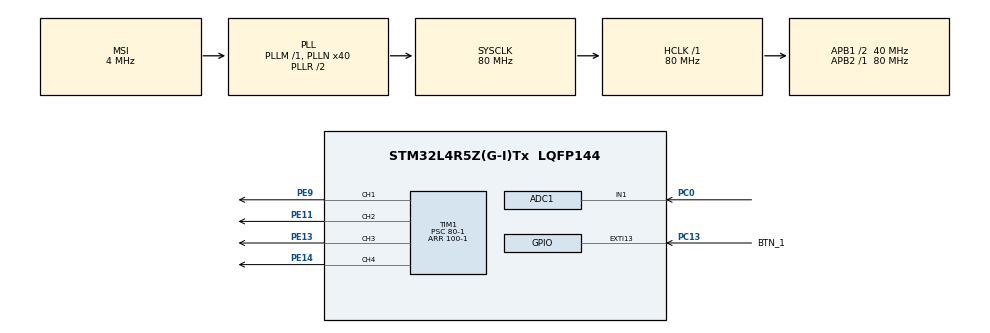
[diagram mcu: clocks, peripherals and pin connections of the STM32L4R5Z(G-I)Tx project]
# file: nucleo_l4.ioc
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ADC1.Channel-0\#ChannelRegularConversion=ADC_CHANNEL_1
ADC1.ClockPrescaler=ADC_CLOCK_ASYNC_DIV6
ADC1.NbrOfConversionFlag=1
ADC1.OffsetNumber-0\#ChannelRegularConversion=ADC_OFFSET_NONE
ADC1.Rank-0\#ChannelRegularConversion=1
ADC1.Resolution=ADC_RESOLUTION_12B
ADC1.SamplingTime-0\#ChannelRegularConversion=ADC_SAMPLETIME_2CYCLES_5
ADC1.master=1
Dma.ADC1.0.Direction=DMA_PERIPH_TO_MEMORY
Dma.ADC1.0.EventEnable=DISABLE
Dma.ADC1.0.Instance=DMA1_Channel1
Dma.ADC1.0.MemDataAlignment=DMA_MDATAALIGN_WORD
Dma.ADC1.0.MemInc=DMA_MINC_ENABLE
Dma.ADC1.0.Mode=DMA_NORMAL
Dma.ADC1.0.PeriphDataAlignment=DMA_PDATAALIGN_WORD
Dma.ADC1.0.PeriphInc=DMA_PINC_DISABLE
Dma.ADC1.0.Polarity=HAL_DMAMUX_REQUEST_GEN_RISING
Dma.ADC1.0.Priority=DMA_PRIORITY_LOW
Dma.ADC1.0.RequestNumber=1
Dma.ADC1.0.SignalID=NONE
Dma.ADC1.0.SyncEnable=DISABLE
Dma.ADC1.0.SyncPolarity=HAL_DMAMUX_SYNC_NO_EVENT
Dma.ADC1.0.SyncRequestNumber=1
Dma.ADC1.0.SyncSignalID=NONE
Dma.Request0=ADC1
Mcu.Family=STM32L4
Mcu.Name=STM32L4R5Z(G-I)Tx
Mcu.Package=LQFP144
NVIC.DMA1_Channel1_IRQn=true\:0\:0\:false\:false\:true\:false\:true\:true
NVIC.EXTI15_10_IRQn=true\:0\:0\:false\:false\:true\:true\:true\:true
NVIC.PriorityGroup=NVIC_PRIORITYGROUP_4
PA13\ (JTMS/SWDIO).GPIO_Label=TMS
PA13\ (JTMS/SWDIO).Mode=Trace_Asynchronous_SW
PA13\ (JTMS/SWDIO).Signal=SYS_JTMS-SWDIO
PA14\ (JTCK/SWCLK).GPIO_Label=TCK
PA14\ (JTCK/SWCLK).Mode=Trace_Asynchronous_SW
PA14\ (JTCK/SWCLK).Signal=SYS_JTCK-SWCLK
PB14.Signal=S_TIM15_CH1
PB3\ (JTDO/TRACESWO).GPIO_Label=SWO
PB3\ (JTDO/TRACESWO).Mode=Trace_Asynchronous_SW
PB3\ (JTDO/TRACESWO).Signal=SYS_JTDO-SWO
PB7.Signal=S_TIM4_CH2
PC0.Signal=ADCx_IN1
PC13.GPIO_Label=BTN_1
PC13.GPIO_ModeDefaultEXTI=GPIO_MODE_IT_FALLING
PC13.Signal=GPXTI13
PC14-OSC32_IN\ (PC14).Mode=LSE-External-Oscillator
PC14-OSC32_IN\ (PC14).Signal=RCC_OSC32_IN
PC15-OSC32_OUT\ (PC15).Mode=LSE-External-Oscillator
PC15-OSC32_OUT\ (PC15).Signal=RCC_OSC32_OUT
PC7.Signal=S_TIM8_CH2
PD8.GPIO_Label=STLK_RX [STM32F103CBT6_PA3]
PD8.Signal=USART3_TX
PD9.GPIO_Label=STLK_TX [STM32F103CBT6_PA2]
PD9.Signal=USART3_RX
PE11.Signal=S_TIM1_CH2
PE13.Signal=S_TIM1_CH3
PE14.Signal=S_TIM1_CH4
PE9.Signal=S_TIM1_CH1
PG7.GPIO_Label=STLINK_TX
PG7.Signal=LPUART1_TX
PG8.GPIO_Label=STLINK_RX
PG8.Signal=LPUART1_RX
PH0-OSC_IN\ (PH0).Mode=HSE-External-Clock-Source
PH0-OSC_IN\ (PH0).Signal=RCC_OSC_IN
PH1-OSC_OUT\ (PH1).Signal=RCC_OSC_OUT
ProjectManager.HeapSize=0x200
ProjectManager.StackSize=0x400
ProjectManager.TargetToolchain=STM32CubeIDE
RCC.48MHZClocksFreq_Value=24000000
RCC.ADCFreq_Value=80000000
RCC.AHBFreq_Value=80000000
RCC.APB1CLKDivider=RCC_HCLK_DIV2
RCC.APB1Freq_Value=40000000
RCC.APB1TimFreq_Value=80000000
RCC.APB2Freq_Value=80000000
RCC.APB2TimFreq_Value=80000000
RCC.CortexFreq_Value=80000000
RCC.HCLKFreq_Value=80000000
RCC.HSE_VALUE=8000000
RCC.HSI48_VALUE=48000000
RCC.HSI_VALUE=16000000
RCC.MSI_VALUE=4000000
RCC.PLLMUL=RCC_PLL_MUL9
RCC.PLLN=40
RCC.PLLSAI1N=40
RCC.PRESCALERUSB=RCC_USBCLKSOURCE_PLL_DIV1_5
RCC.SYSCLKFreq_VALUE=80000000
RCC.SYSCLKSource=RCC_SYSCLKSOURCE_PLLCLK
RCC.SYSCLKSourceVirtual=RCC_SYSCLKSOURCE_PLLCLK
RCC.USBFreq_Value=80000000
RCC.VCOOutputFreq_Value=160000000
SH.ADCx_IN1.0=ADC1_IN1,IN1-Single-Ended
SH.S_TIM15_CH1.0=TIM15_CH1
SH.S_TIM1_CH1.0=TIM1_CH1,PWM Generation1 CH1
SH.S_TIM1_CH2.0=TIM1_CH2,PWM Generation2 CH2
SH.S_TIM1_CH3.0=TIM1_CH3,PWM Generation3 CH3
SH.S_TIM1_CH4.0=TIM1_CH4,PWM Generation4 CH4
SH.S_TIM4_CH2.0=TIM4_CH2
SH.S_TIM8_CH2.0=TIM8_CH2
TIM1.Channel-PWM\ Generation1\ CH1=TIM_CHANNEL_1
TIM1.Channel-PWM\ Generation2\ CH2=TIM_CHANNEL_2
TIM1.Channel-PWM\ Generation3\ CH3=TIM_CHANNEL_3
TIM1.Channel-PWM\ Generation4\ CH4=TIM_CHANNEL_4
TIM1.CounterMode=TIM_COUNTERMODE_UP
TIM1.Period=100-1
TIM1.Prescaler=80-1
board=NUCLEO-L4R5ZI

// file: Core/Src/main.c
/* USER CODE BEGIN Header */
/**
  ******************************************************************************
  * @file           : main.c
  * @brief          : Main program body
  ******************************************************************************
  * @attention
  *
  * Copyright (c) 2025 STMicroelectronics.
  * All rights reserved.
  *
  * This software is licensed under terms that can be found in the LICENSE file
  * in the root directory of this software component.
  * If no LICENSE file comes with this software, it is provided AS-IS.
  *
  ******************************************************************************
  */
/* USER CODE END Header */
#include "main.h"

/* USER CODE BEGIN Includes */
#include "lazer_isaretleyici.h"
/* USER CODE END Includes */

ADC_HandleTypeDef hadc1;
DMA_HandleTypeDef hdma_adc1;

TIM_HandleTypeDef htim1;

void SystemClock_Config(void);
static void MX_GPIO_Init(void);
static void MX_DMA_Init(void);
static void MX_TIM1_Init(void);
static void MX_ADC1_Init(void);

int main(void)
{

  /* MCU Configuration--------------------------------------------------------*/

  /* Reset of all peripherals, Initializes the Flash interface and the Systick. */
  HAL_Init();

  /* Configure the system clock */
  SystemClock_Config();

  /* Initialize all configured peripherals */
  MX_GPIO_Init();
  MX_DMA_Init();
  MX_TIM1_Init();
  MX_ADC1_Init();
  /* USER CODE BEGIN 2 */
  StartPWM();

  /* USER CODE END 2 */

  /* Infinite loop */
  /* USER CODE BEGIN WHILE */

  while (1)
  {
	  DeviceModeHandler();
	  ChangeDeviceMode(adcbuffer);
    /* USER CODE END WHILE */

  }
}

void SystemClock_Config(void)
{
  RCC_OscInitTypeDef RCC_OscInitStruct = {0};
  RCC_ClkInitTypeDef RCC_ClkInitStruct = {0};

  /** Configure the main internal regulator output voltage
  */
  if (HAL_PWREx_ControlVoltageScaling(PWR_REGULATOR_VOLTAGE_SCALE1) != HAL_OK)
  {
    Error_Handler();
  }

  /** Initializes the RCC Oscillators according to the specified parameters
  * in the RCC_OscInitTypeDef structure.
  */
  RCC_OscInitStruct.OscillatorType = RCC_OSCILLATORTYPE_MSI;
  RCC_OscInitStruct.MSIState = RCC_MSI_ON;
  RCC_OscInitStruct.MSICalibrationValue = 0;
  RCC_OscInitStruct.MSIClockRange = RCC_MSIRANGE_6;
  RCC_OscInitStruct.PLL.PLLState = RCC_PLL_ON;
  RCC_OscInitStruct.PLL.PLLSource = RCC_PLLSOURCE_MSI;
  RCC_OscInitStruct.PLL.PLLM = 1;
  RCC_OscInitStruct.PLL.PLLN = 40;
  RCC_OscInitStruct.PLL.PLLP = RCC_PLLP_DIV2;
  RCC_OscInitStruct.PLL.PLLQ = RCC_PLLQ_DIV2;
  RCC_OscInitStruct.PLL.PLLR = RCC_PLLR_DIV2;
  if (HAL_RCC_OscConfig(&RCC_OscInitStruct) != HAL_OK)
  {
    Error_Handler();
  }

  /** Initializes the CPU, AHB and APB buses clocks
  */
  RCC_ClkInitStruct.ClockType = RCC_CLOCKTYPE_HCLK|RCC_CLOCKTYPE_SYSCLK
                              |RCC_CLOCKTYPE_PCLK1|RCC_CLOCKTYPE_PCLK2;
  RCC_ClkInitStruct.SYSCLKSource = RCC_SYSCLKSOURCE_PLLCLK;
  RCC_ClkInitStruct.AHBCLKDivider = RCC_SYSCLK_DIV1;
  RCC_ClkInitStruct.APB1CLKDivider = RCC_HCLK_DIV2;
  RCC_ClkInitStruct.APB2CLKDivider = RCC_HCLK_DIV1;

  if (HAL_RCC_ClockConfig(&RCC_ClkInitStruct, FLASH_LATENCY_3) != HAL_OK)
  {
    Error_Handler();
  }
}

static void MX_ADC1_Init(void)
{

  ADC_ChannelConfTypeDef sConfig = {0};

  /** Common config
  */
  hadc1.Instance = ADC1;
  hadc1.Init.ClockPrescaler = ADC_CLOCK_ASYNC_DIV6;
  hadc1.Init.Resolution = ADC_RESOLUTION_12B;
  hadc1.Init.DataAlign = ADC_DATAALIGN_RIGHT;
  hadc1.Init.ScanConvMode = ADC_SCAN_DISABLE;
  hadc1.Init.EOCSelection = ADC_EOC_SINGLE_CONV;
  hadc1.Init.LowPowerAutoWait = DISABLE;
  hadc1.Init.ContinuousConvMode = DISABLE;
  hadc1.Init.NbrOfConversion = 1;
  hadc1.Init.DiscontinuousConvMode = DISABLE;
  hadc1.Init.ExternalTrigConv = ADC_SOFTWARE_START;
  hadc1.Init.ExternalTrigConvEdge = ADC_EXTERNALTRIGCONVEDGE_NONE;
  hadc1.Init.DMAContinuousRequests = DISABLE;
  hadc1.Init.Overrun = ADC_OVR_DATA_PRESERVED;
  hadc1.Init.OversamplingMode = DISABLE;
  if (HAL_ADC_Init(&hadc1) != HAL_OK)
  {
    Error_Handler();
  }

  /** Configure Regular Channel
  */
  sConfig.Channel = ADC_CHANNEL_1;
  sConfig.Rank = ADC_REGULAR_RANK_1;
  sConfig.SamplingTime = ADC_SAMPLETIME_2CYCLES_5;
  sConfig.SingleDiff = ADC_SINGLE_ENDED;
  sConfig.OffsetNumber = ADC_OFFSET_NONE;
  sConfig.Offset = 0;
  if (HAL_ADC_ConfigChannel(&hadc1, &sConfig) != HAL_OK)
  {
    Error_Handler();
  }

}

static void MX_TIM1_Init(void)
{

  TIM_MasterConfigTypeDef sMasterConfig = {0};
  TIM_OC_InitTypeDef sConfigOC = {0};
  TIM_BreakDeadTimeConfigTypeDef sBreakDeadTimeConfig = {0};

  htim1.Instance = TIM1;
  htim1.Init.Prescaler = 80-1;
  htim1.Init.CounterMode = TIM_COUNTERMODE_UP;
  htim1.Init.Period = 100-1;
  htim1.Init.ClockDivision = TIM_CLOCKDIVISION_DIV1;
  htim1.Init.RepetitionCounter = 0;
  htim1.Init.AutoReloadPreload = TIM_AUTORELOAD_PRELOAD_DISABLE;
  if (HAL_TIM_PWM_Init(&htim1) != HAL_OK)
  {
    Error_Handler();
  }
  sMasterConfig.MasterOutputTrigger = TIM_TRGO_RESET;
  sMasterConfig.MasterOutputTrigger2 = TIM_TRGO2_RESET;
  sMasterConfig.MasterSlaveMode = TIM_MASTERSLAVEMODE_DISABLE;
  if (HAL_TIMEx_MasterConfigSynchronization(&htim1, &sMasterConfig) != HAL_OK)
  {
    Error_Handler();
  }
  sConfigOC.OCMode = TIM_OCMODE_PWM1;
  sConfigOC.Pulse = 0;
  sConfigOC.OCPolarity = TIM_OCPOLARITY_HIGH;
  sConfigOC.OCNPolarity = TIM_OCNPOLARITY_HIGH;
  sConfigOC.OCFastMode = TIM_OCFAST_DISABLE;
  sConfigOC.OCIdleState = TIM_OCIDLESTATE_RESET;
  sConfigOC.OCNIdleState = TIM_OCNIDLESTATE_RESET;
  if (HAL_TIM_PWM_ConfigChannel(&htim1, &sConfigOC, TIM_CHANNEL_1) != HAL_OK)
  {
    Error_Handler();
  }
  if (HAL_TIM_PWM_ConfigChannel(&htim1, &sConfigOC, TIM_CHANNEL_2) != HAL_OK)
  {
    Error_Handler();
  }
  if (HAL_TIM_PWM_ConfigChannel(&htim1, &sConfigOC, TIM_CHANNEL_3) != HAL_OK)
  {
    Error_Handler();
  }
  if (HAL_TIM_PWM_ConfigChannel(&htim1, &sConfigOC, TIM_CHANNEL_4) != HAL_OK)
  {
    Error_Handler();
  }
  sBreakDeadTimeConfig.OffStateRunMode = TIM_OSSR_DISABLE;
  sBreakDeadTimeConfig.OffStateIDLEMode = TIM_OSSI_DISABLE;
  sBreakDeadTimeConfig.LockLevel = TIM_LOCKLEVEL_OFF;
  sBreakDeadTimeConfig.DeadTime = 0;
  sBreakDeadTimeConfig.BreakState = TIM_BREAK_DISABLE;
  sBreakDeadTimeConfig.BreakPolarity = TIM_BREAKPOLARITY_HIGH;
  sBreakDeadTimeConfig.BreakFilter = 0;
  sBreakDeadTimeConfig.Break2State = TIM_BREAK2_DISABLE;
  sBreakDeadTimeConfig.Break2Polarity = TIM_BREAK2POLARITY_HIGH;
  sBreakDeadTimeConfig.Break2Filter = 0;
  sBreakDeadTimeConfig.AutomaticOutput = TIM_AUTOMATICOUTPUT_DISABLE;
  if (HAL_TIMEx_ConfigBreakDeadTime(&htim1, &sBreakDeadTimeConfig) != HAL_OK)
  {
    Error_Handler();
  }
  HAL_TIM_MspPostInit(&htim1);

}

static void MX_DMA_Init(void)
{

  /* DMA controller clock enable */
  __HAL_RCC_DMAMUX1_CLK_ENABLE();
  __HAL_RCC_DMA1_CLK_ENABLE();

  /* DMA interrupt init */
  /* DMA1_Channel1_IRQn interrupt configuration */
  HAL_NVIC_SetPriority(DMA1_Channel1_IRQn, 0, 0);
  HAL_NVIC_EnableIRQ(DMA1_Channel1_IRQn);

}

static void MX_GPIO_Init(void)
{
  GPIO_InitTypeDef GPIO_InitStruct = {0};

  /* GPIO Ports Clock Enable */
  __HAL_RCC_GPIOC_CLK_ENABLE();
  __HAL_RCC_GPIOH_CLK_ENABLE();
  __HAL_RCC_GPIOE_CLK_ENABLE();
  __HAL_RCC_GPIOB_CLK_ENABLE();
  __HAL_RCC_GPIOD_CLK_ENABLE();
  __HAL_RCC_GPIOG_CLK_ENABLE();
  HAL_PWREx_EnableVddIO2();
  __HAL_RCC_GPIOA_CLK_ENABLE();

  /*Configure GPIO pin : BTN_1_Pin */
  GPIO_InitStruct.Pin = BTN_1_Pin;
  GPIO_InitStruct.Mode = GPIO_MODE_IT_FALLING;
  GPIO_InitStruct.Pull = GPIO_NOPULL;
  HAL_GPIO_Init(BTN_1_GPIO_Port, &GPIO_InitStruct);

  /*Configure GPIO pin : PB14 */
  GPIO_InitStruct.Pin = GPIO_PIN_14;
  GPIO_InitStruct.Mode = GPIO_MODE_AF_PP;
  GPIO_InitStruct.Pull = GPIO_NOPULL;
  GPIO_InitStruct.Speed = GPIO_SPEED_FREQ_LOW;
  GPIO_InitStruct.Alternate = GPIO_AF14_TIM15;
  HAL_GPIO_Init(GPIOB, &GPIO_InitStruct);

  /*Configure GPIO pins : STLK_RX_Pin STLK_TX_Pin */
  GPIO_InitStruct.Pin = STLK_RX_Pin|STLK_TX_Pin;
  GPIO_InitStruct.Mode = GPIO_MODE_AF_PP;
  GPIO_InitStruct.Pull = GPIO_NOPULL;
  GPIO_InitStruct.Speed = GPIO_SPEED_FREQ_VERY_HIGH;
  GPIO_InitStruct.Alternate = GPIO_AF7_USART3;
  HAL_GPIO_Init(GPIOD, &GPIO_InitStruct);

  /*Configure GPIO pins : STLINK_TX_Pin STLINK_RX_Pin */
  GPIO_InitStruct.Pin = STLINK_TX_Pin|STLINK_RX_Pin;
  GPIO_InitStruct.Mode = GPIO_MODE_AF_PP;
  GPIO_InitStruct.Pull = GPIO_NOPULL;
  GPIO_InitStruct.Speed = GPIO_SPEED_FREQ_VERY_HIGH;
  GPIO_InitStruct.Alternate = GPIO_AF8_LPUART1;
  HAL_GPIO_Init(GPIOG, &GPIO_InitStruct);

  /*Configure GPIO pin : PC7 */
  GPIO_InitStruct.Pin = GPIO_PIN_7;
  GPIO_InitStruct.Mode = GPIO_MODE_AF_PP;
  GPIO_InitStruct.Pull = GPIO_NOPULL;
  GPIO_InitStruct.Speed = GPIO_SPEED_FREQ_LOW;
  GPIO_InitStruct.Alternate = GPIO_AF3_TIM8;
  HAL_GPIO_Init(GPIOC, &GPIO_InitStruct);

  /*Configure GPIO pin : PB7 */
  GPIO_InitStruct.Pin = GPIO_PIN_7;
  GPIO_InitStruct.Mode = GPIO_MODE_AF_PP;
  GPIO_InitStruct.Pull = GPIO_NOPULL;
  GPIO_InitStruct.Speed = GPIO_SPEED_FREQ_LOW;
  GPIO_InitStruct.Alternate = GPIO_AF2_TIM4;
  HAL_GPIO_Init(GPIOB, &GPIO_InitStruct);

  /* EXTI interrupt init*/
  HAL_NVIC_SetPriority(EXTI15_10_IRQn, 0, 0);
  HAL_NVIC_EnableIRQ(EXTI15_10_IRQn);

}

void Error_Handler(void)
{
  __disable_irq();
  while (1)
  {
  }
}
